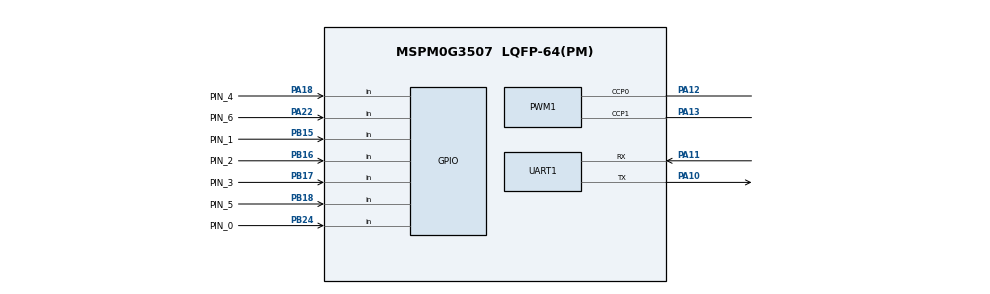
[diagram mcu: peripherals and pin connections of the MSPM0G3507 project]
/**
 * These arguments were used when this file was generated. They will be automatically applied on subsequent loads
 * via the GUI or CLI. Run CLI with '--help' for additional information on how to override these arguments.
 * @cliArgs --device "MSPM0G350X" --part "Default" --package "LQFP-64(PM)" --product "mspm0_sdk@2.10.00.04"
 * @v2CliArgs --device "MSPM0G3507" --package "LQFP-64(PM)" --product "mspm0_sdk@2.10.00.04"
 * @versions {"tool":"1.26.2+4477"}
 */

/**
 * Import the modules used in this configuration.
 */
const GPIO   = scripting.addModule("/ti/driverlib/GPIO", {}, false);
const GPIO1  = GPIO.addInstance();
const GPIO2  = GPIO.addInstance();
const GPIO3  = GPIO.addInstance();
const GPIO4  = GPIO.addInstance();
const PWM    = scripting.addModule("/ti/driverlib/PWM", {}, false);
const PWM1   = PWM.addInstance();
const SYSCTL = scripting.addModule("/ti/driverlib/SYSCTL");
const TIMER  = scripting.addModule("/ti/driverlib/TIMER", {}, false);
const TIMER1 = TIMER.addInstance();
const UART   = scripting.addModule("/ti/driverlib/UART", {}, false);
const UART1  = UART.addInstance();

/**
 * Write custom configuration values to the imported modules.
 */
GPIO1.$name                              = "GPIO_LED";
GPIO1.associatedPins[0].$name            = "PIN_LED1";
GPIO1.associatedPins[0].assignedPort     = "PORTA";
GPIO1.associatedPins[0].assignedPin      = "0";
GPIO1.associatedPins[0].internalResistor = "PULL_UP";

const Board = scripting.addModule("/ti/driverlib/Board", {}, false);

GPIO2.$name                              = "GPIO_KEY";
GPIO2.associatedPins[0].direction        = "INPUT";
GPIO2.associatedPins[0].assignedPort     = "PORTB";
GPIO2.associatedPins[0].assignedPin      = "21";
GPIO2.associatedPins[0].internalResistor = "PULL_UP";
GPIO2.associatedPins[0].$name            = "PIN_KEY1";

GPIO3.$name                          = "GPIO_MOTOR";
GPIO3.associatedPins.create(4);
GPIO3.associatedPins[0].assignedPort = "PORTB";
GPIO3.associatedPins[0].assignedPin  = "2";
GPIO3.associatedPins[0].$name        = "A_1";
GPIO3.associatedPins[1].assignedPort = "PORTB";
GPIO3.associatedPins[1].assignedPin  = "3";
GPIO3.associatedPins[1].$name        = "A_2";
GPIO3.associatedPins[2].assignedPort = "PORTB";
GPIO3.associatedPins[2].assignedPin  = "6";
GPIO3.associatedPins[2].$name        = "B_1";
GPIO3.associatedPins[3].assignedPort = "PORTB";
GPIO3.associatedPins[3].assignedPin  = "7";
GPIO3.associatedPins[3].$name        = "B_2";

GPIO4.$name                              = "GPIO_XUNJI";
GPIO4.associatedPins.create(7);
GPIO4.associatedPins[0].$name            = "PIN_0";
GPIO4.associatedPins[0].direction        = "INPUT";
GPIO4.associatedPins[0].assignedPort     = "PORTB";
GPIO4.associatedPins[0].internalResistor = "PULL_UP";
GPIO4.associatedPins[0].assignedPin      = "24";
GPIO4.associatedPins[0].pin.$assign      = "PB24";
GPIO4.associatedPins[1].$name            = "PIN_1";
GPIO4.associatedPins[1].internalResistor = "PULL_UP";
GPIO4.associatedPins[1].direction        = "INPUT";
GPIO4.associatedPins[1].assignedPort     = "PORTB";
GPIO4.associatedPins[1].assignedPin      = "15";
GPIO4.associatedPins[1].pin.$assign      = "PB15";
GPIO4.associatedPins[2].$name            = "PIN_2";
GPIO4.associatedPins[2].internalResistor = "PULL_UP";
GPIO4.associatedPins[2].direction        = "INPUT";
GPIO4.associatedPins[2].assignedPort     = "PORTB";
GPIO4.associatedPins[2].assignedPin      = "16";
GPIO4.associatedPins[2].pin.$assign      = "PB16";
GPIO4.associatedPins[3].$name            = "PIN_3";
GPIO4.associatedPins[3].internalResistor = "PULL_UP";
GPIO4.associatedPins[3].direction        = "INPUT";
GPIO4.associatedPins[3].assignedPort     = "PORTB";
GPIO4.associatedPins[3].assignedPin      = "17";
GPIO4.associatedPins[3].pin.$assign      = "PB17";
GPIO4.associatedPins[4].$name            = "PIN_4";
GPIO4.associatedPins[4].internalResistor = "PULL_UP";
GPIO4.associatedPins[4].direction        = "INPUT";
GPIO4.associatedPins[4].assignedPort     = "PORTA";
GPIO4.associatedPins[4].assignedPin      = "18";
GPIO4.associatedPins[4].pin.$assign      = "PA18";
GPIO4.associatedPins[5].$name            = "PIN_5";
GPIO4.associatedPins[5].internalResistor = "PULL_UP";
GPIO4.associatedPins[5].direction        = "INPUT";
GPIO4.associatedPins[5].assignedPort     = "PORTB";
GPIO4.associatedPins[5].assignedPin      = "18";
GPIO4.associatedPins[5].pin.$assign      = "PB18";
GPIO4.associatedPins[6].$name            = "PIN_6";
GPIO4.associatedPins[6].internalResistor = "PULL_UP";
GPIO4.associatedPins[6].direction        = "INPUT";
GPIO4.associatedPins[6].assignedPort     = "PORTA";
GPIO4.associatedPins[6].assignedPin      = "22";
GPIO4.associatedPins[6].pin.$assign      = "PA22";

PWM1.$name                      = "PWM_0";
PWM1.pwmMode                    = "EDGE_ALIGN_UP";
PWM1.timerCount                 = 3200;
PWM1.peripheral.$assign         = "TIMG0";
PWM1.peripheral.ccp0Pin.$assign = "PA12";
PWM1.peripheral.ccp1Pin.$assign = "PA13";
PWM1.PWM_CHANNEL_0.$name        = "ti_driverlib_pwm_PWMTimerCC0";
PWM1.PWM_CHANNEL_1.$name        = "ti_driverlib_pwm_PWMTimerCC1";
PWM1.ccp0PinConfig.$name        = "ti_driverlib_gpio_GPIOPinGeneric0";
PWM1.ccp1PinConfig.$name        = "ti_driverlib_gpio_GPIOPinGeneric1";

SYSCTL.forceDefaultClkConfig = true;

TIMER1.$name              = "TIMER_0";
TIMER1.timerClkPrescale   = 32;
TIMER1.timerPeriod        = "1ms";
TIMER1.timerStartTimer    = true;
TIMER1.timerMode          = "PERIODIC_UP";
TIMER1.interrupts         = ["ZERO"];
TIMER1.peripheral.$assign = "TIMA0";

UART1.$name                    = "UART_0";
UART1.enabledInterrupts        = ["RX"];
UART1.peripheral.$assign       = "UART0";
UART1.peripheral.rxPin.$assign = "PA11";
UART1.peripheral.txPin.$assign = "PA10";
UART1.txPinConfig.$name        = "ti_driverlib_gpio_GPIOPinGeneric2";
UART1.rxPinConfig.$name        = "ti_driverlib_gpio_GPIOPinGeneric3";

/**
 * Pinmux solution for unlocked pins/peripherals. This ensures that minor changes to the automatic solver in a future
 * version of the tool will not impact the pinmux you originally saw.  These lines can be completely deleted in order to
 * re-solve from scratch.
 */
GPIO1.associatedPins[0].pin.$suggestSolution = "PA0";
Board.peripheral.$suggestSolution            = "DEBUGSS";
Board.peripheral.swclkPin.$suggestSolution   = "PA20";
Board.peripheral.swdioPin.$suggestSolution   = "PA19";
GPIO2.associatedPins[0].pin.$suggestSolution = "PB21";
GPIO3.associatedPins[0].pin.$suggestSolution = "PB2";
GPIO3.associatedPins[1].pin.$suggestSolution = "PB3";
GPIO3.associatedPins[2].pin.$suggestSolution = "PB6";
GPIO3.associatedPins[3].pin.$suggestSolution = "PB7";
SYSCTL.peripheral.$suggestSolution           = "SYSCTL";
